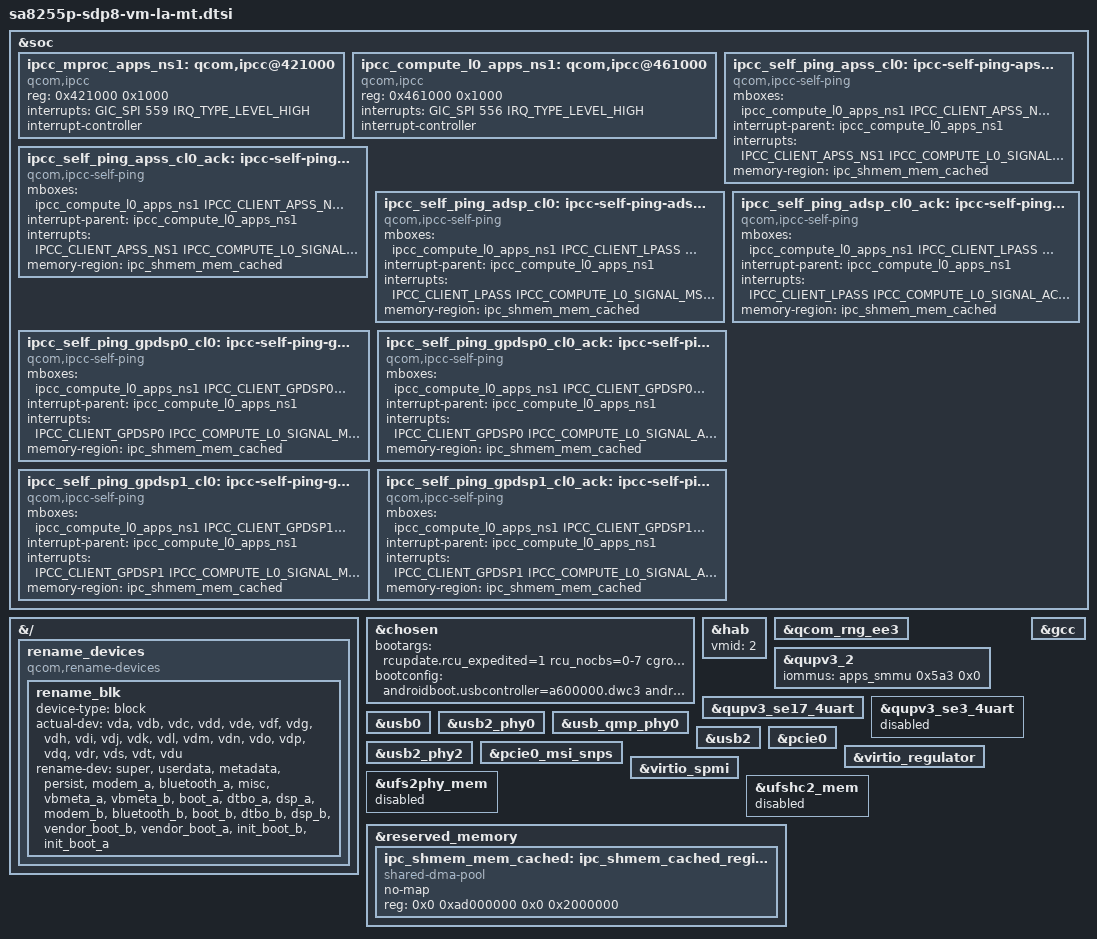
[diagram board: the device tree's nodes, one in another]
// SPDX-License-Identifier: BSD-3-Clause
/*
 * Copyright (c) Qualcomm Technologies, Inc. and/or its subsidiaries.
 */

#include <dt-bindings/mailbox/qcom-ipcc.h>

&soc {
	ipcc_mproc_apps_ns1: qcom,ipcc@421000 {
		compatible = "qcom,ipcc";
		reg = <0x421000 0x1000>;
		interrupts = <GIC_SPI 559 IRQ_TYPE_LEVEL_HIGH>;
		interrupt-controller;
		#interrupt-cells = <3>;
		#mbox-cells = <2>;
	};

	ipcc_compute_l0_apps_ns1: qcom,ipcc@461000 {
		compatible = "qcom,ipcc";
		reg = <0x461000 0x1000>;
		interrupts = <GIC_SPI 556 IRQ_TYPE_LEVEL_HIGH>;
		interrupt-controller;
		#interrupt-cells = <3>;
		#mbox-cells = <2>;
		status = "ok";
	};
};

&{/} {
	rename_devices: rename_devices {
		compatible = "qcom,rename-devices";
		rename_blk: rename_blk {
			device-type = "block";
			actual-dev = "vda", "vdb", "vdc",
					"vdd", "vde", "vdf",
					"vdg", "vdh", "vdi",
					"vdj", "vdk", "vdl",
					"vdm", "vdn", "vdo",
					"vdp", "vdq", "vdr",
					"vds", "vdt", "vdu";
			rename-dev = "super", "userdata", "metadata",
					"persist", "modem_a","bluetooth_a",
					"misc", "vbmeta_a", "vbmeta_b",
					"boot_a", "dtbo_a", "dsp_a",
					"modem_b", "bluetooth_b", "boot_b",
					"dtbo_b", "dsp_b", "vendor_boot_b",
					"vendor_boot_a", "init_boot_b", "init_boot_a";
		};
	};
};

&chosen {
	bootargs ="rcupdate.rcu_expedited=1 rcu_nocbs=0-7 cgroup.memory=nokmem,nosocket kpti=0 ufshcd-core.use_mcq_mode=n qcom_dma_heaps.enable_bitstream_contig_heap=y arm64.nopauth kasan=off msm_    show_resume_irq.debug_mask=1 fw_devlink.strict=1";
	bootconfig = "androidboot.usbcontroller=a600000.dwc3 androidboot.fstab_suffix=gen4.qcom androidboot.dtbo_idx=17";
};

&hab {
	vmid = <2>;
};

&qcom_rng_ee3 {
	status = "ok";
};

&qupv3_2 {
	iommus = <&apps_smmu 0x5a3  0x0>;
	status = "ok";
};

&qupv3_se17_4uart {
	status = "ok";
};

&qupv3_se3_4uart {
	status = "disabled";
};

&usb0 {
	status = "ok";
};

&usb2_phy0 {
	status = "ok";
};

&usb_qmp_phy0 {
	status = "ok";
};

&usb2 {
	status = "ok";
};

&usb2_phy2 {
	status = "ok";
};

&pcie0 {
	status = "ok";
};

&pcie0_msi_snps {
	status = "ok";
};

&gcc {
	status = "ok";
};

&virtio_regulator {
	status = "ok";
};

&virtio_spmi {
	status = "ok";
};

&qcom_rng_ee3 {
	status = "ok";
};
&ufs2phy_mem {
	status = "disabled";
};

&ufshc2_mem {
	status = "disabled";
};

&reserved_memory {
	ipc_shmem_mem_cached: ipc_shmem_cached_region {
		compatible = "shared-dma-pool";
		no-map;
		reg = <0x0 0xad000000 0x0 0x2000000>;
	};
};

&soc {
	ipcc_compute_l0_apps_ns1: qcom,ipcc@461000 {
		compatible = "qcom,ipcc";
		reg = <0x461000 0x1000>;
		interrupts = <GIC_SPI 556 IRQ_TYPE_LEVEL_HIGH>;
		interrupt-controller;
		#interrupt-cells = <3>;
		#mbox-cells = <2>;
		status = "ok";
	};

	ipcc_self_ping_apss_cl0: ipcc-self-ping-apss_cl0 {
		compatible = "qcom,ipcc-self-ping";
		mboxes = <&ipcc_compute_l0_apps_ns1 IPCC_CLIENT_APSS_NS1
				IPCC_COMPUTE_L0_SIGNAL_MSG>;
		interrupt-parent = <&ipcc_compute_l0_apps_ns1>;
		interrupts = <IPCC_CLIENT_APSS_NS1
				IPCC_COMPUTE_L0_SIGNAL_MSG
				IRQ_TYPE_EDGE_RISING>;
		memory-region = <&ipc_shmem_mem_cached>;
	};

	ipcc_self_ping_apss_cl0_ack: ipcc-self-ping-apss_cl0_ack {
		compatible = "qcom,ipcc-self-ping";
		mboxes = <&ipcc_compute_l0_apps_ns1 IPCC_CLIENT_APSS_NS1
				IPCC_COMPUTE_L0_SIGNAL_ACK>;
		interrupt-parent = <&ipcc_compute_l0_apps_ns1>;
		interrupts = <IPCC_CLIENT_APSS_NS1
				IPCC_COMPUTE_L0_SIGNAL_ACK
				IRQ_TYPE_EDGE_RISING>;
		memory-region = <&ipc_shmem_mem_cached>;
	};

	ipcc_self_ping_adsp_cl0: ipcc-self-ping-adsp_cl0 {
		compatible = "qcom,ipcc-self-ping";
		mboxes = <&ipcc_compute_l0_apps_ns1 IPCC_CLIENT_LPASS
				IPCC_COMPUTE_L0_SIGNAL_MSG>;
		interrupt-parent = <&ipcc_compute_l0_apps_ns1>;
		interrupts = <IPCC_CLIENT_LPASS
				IPCC_COMPUTE_L0_SIGNAL_MSG
				IRQ_TYPE_EDGE_RISING>;
		memory-region = <&ipc_shmem_mem_cached>;
	};

	ipcc_self_ping_adsp_cl0_ack: ipcc-self-ping-adsp_cl0_ack {
		compatible = "qcom,ipcc-self-ping";
		mboxes = <&ipcc_compute_l0_apps_ns1 IPCC_CLIENT_LPASS
				IPCC_COMPUTE_L0_SIGNAL_ACK>;
		interrupt-parent = <&ipcc_compute_l0_apps_ns1>;
		interrupts = <IPCC_CLIENT_LPASS
				IPCC_COMPUTE_L0_SIGNAL_ACK
				IRQ_TYPE_EDGE_RISING>;
		memory-region = <&ipc_shmem_mem_cached>;
	};

	ipcc_self_ping_gpdsp0_cl0: ipcc-self-ping-gpdsp0_cl0 {
		compatible = "qcom,ipcc-self-ping";
		mboxes = <&ipcc_compute_l0_apps_ns1 IPCC_CLIENT_GPDSP0
				IPCC_COMPUTE_L0_SIGNAL_MSG>;
		interrupt-parent = <&ipcc_compute_l0_apps_ns1>;
		interrupts = <IPCC_CLIENT_GPDSP0
				IPCC_COMPUTE_L0_SIGNAL_MSG
				IRQ_TYPE_EDGE_RISING>;
		memory-region = <&ipc_shmem_mem_cached>;
	};

	ipcc_self_ping_gpdsp0_cl0_ack: ipcc-self-ping-gpdsp0_cl0_ack {
		compatible = "qcom,ipcc-self-ping";
		mboxes = <&ipcc_compute_l0_apps_ns1 IPCC_CLIENT_GPDSP0
				IPCC_COMPUTE_L0_SIGNAL_ACK>;
		interrupt-parent = <&ipcc_compute_l0_apps_ns1>;
		interrupts = <IPCC_CLIENT_GPDSP0
				IPCC_COMPUTE_L0_SIGNAL_ACK
				IRQ_TYPE_EDGE_RISING>;
		memory-region = <&ipc_shmem_mem_cached>;
	};

	ipcc_self_ping_gpdsp1_cl0: ipcc-self-ping-gpdsp1_cl0 {
		compatible = "qcom,ipcc-self-ping";
		mboxes = <&ipcc_compute_l0_apps_ns1 IPCC_CLIENT_GPDSP1
				IPCC_COMPUTE_L0_SIGNAL_MSG>;
		interrupt-parent = <&ipcc_compute_l0_apps_ns1>;
		interrupts = <IPCC_CLIENT_GPDSP1
				IPCC_COMPUTE_L0_SIGNAL_MSG
				IRQ_TYPE_EDGE_RISING>;
		memory-region = <&ipc_shmem_mem_cached>;
	};

	ipcc_self_ping_gpdsp1_cl0_ack: ipcc-self-ping-gpdsp1_cl0_ack {
		compatible = "qcom,ipcc-self-ping";
		mboxes = <&ipcc_compute_l0_apps_ns1 IPCC_CLIENT_GPDSP1
				IPCC_COMPUTE_L0_SIGNAL_ACK>;
		interrupt-parent = <&ipcc_compute_l0_apps_ns1>;
		interrupts = <IPCC_CLIENT_GPDSP1
				IPCC_COMPUTE_L0_SIGNAL_ACK
				IRQ_TYPE_EDGE_RISING>;
		memory-region = <&ipc_shmem_mem_cached>;
	};

};
